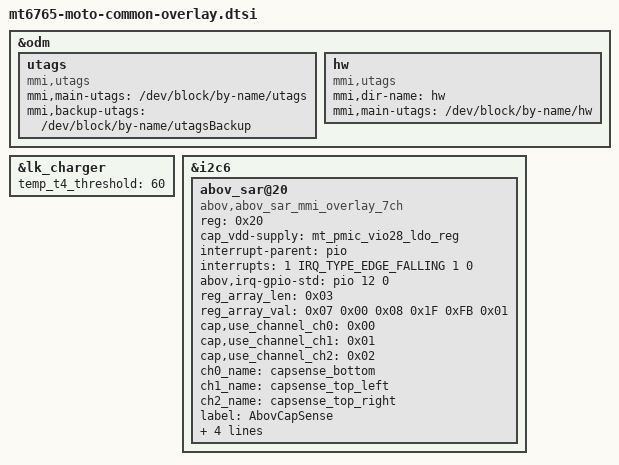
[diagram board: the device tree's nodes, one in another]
/* Copyright (c) 2020, The Linux Foundation. All rights reserved.
 *
 * This program is free software; you can redistribute it and/or modify
 * it under the terms of the GNU General Public License version 2 and
 * only version 2 as published by the Free Software Foundation.
 *
 * This program is distributed in the hope that it will be useful,
 * but WITHOUT ANY WARRANTY; without even the implied warranty of
 * MERCHANTABILITY or FITNESS FOR A PARTICULAR PURPOSE.  See the
 * GNU General Public License for more details.
 */
/dts-v1/;
/plugin/;
#include <dt-bindings/interrupt-controller/irq.h>
#include <dt-bindings/interrupt-controller/arm-gic.h>
#include <dt-bindings/pinctrl/mt6765-pinfunc.h>
#include "carrier-channel-ids.dtsi"

&odm {
	utags {
		compatible = "mmi,utags";
		mmi,main-utags = "/dev/block/by-name/utags";
		mmi,backup-utags = "/dev/block/by-name/utagsBackup";
	};
	hw {
		compatible = "mmi,utags";
		mmi,dir-name = "hw";
		mmi,main-utags = "/dev/block/by-name/hw";
	};
};

&lk_charger {
	temp_t4_threshold = <60>;
};

&i2c6 {
    status = "ok";

    abov_sar@20 {
        status = "ok";
        compatible = "abov,abov_sar_mmi_overlay_7ch";
        reg = <0x20>;
        cap_vdd-supply = <&mt_pmic_vio28_ldo_reg>;
        interrupt-parent = <&pio>;
        interrupts = <1 IRQ_TYPE_EDGE_FALLING 1 0>;
        abov,irq-gpio-std = <&pio 12 0>;
        reg_array_len = <0x03>;
        reg_array_val = <0x07 0x00 0x08 0x1F 0xFB 0x01>;
        cap,use_channel_ch0 = <0x00>;
        cap,use_channel_ch1 = <0x01>;
        cap,use_channel_ch2 = <0x02>;
        ch0_name = "capsense_bottom";
        ch1_name = "capsense_top_left";
        ch2_name = "capsense_top_right";
        label = "AbovCapSense";
        cap,channel_number = <0x03>;
        cap,fw_mode_ret = <0x39>;
        button_mask = <0x15>;
        cap,flash_erase_time = <1400>;
    };
};

